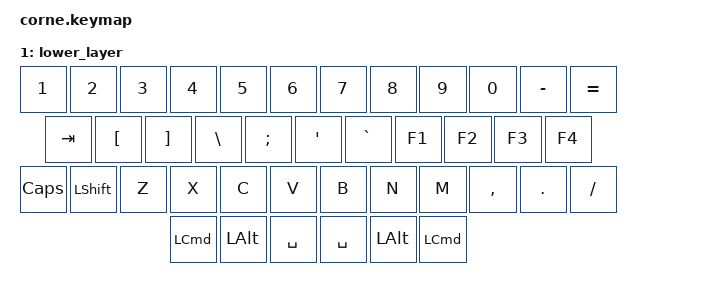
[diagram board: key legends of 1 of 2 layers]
#include <behaviors.dtsi>
#include <dt-bindings/zmk/bt.h>
#include <dt-bindings/zmk/keys.h>
#include <dt-bindings/zmk/outputs.h>

/ {
    keymap {
        compatible = "zmk,keymap";

        default_layer {
            bindings = <
&kp Q &kp W &kp E &kp R &kp T &kp Y  &kp Y &kp U &kp I &kp O &kp P &kp BACKSPACE
&kp A &kp S &kp D &kp F &kp G       &kp H &kp J &kp K &kp L &kp SEMICOLON &kp ENTER
&kp Z &kp X &kp C &kp V &kp B       &kp N &kp M &kp COMMA &kp DOT &kp SLASH &kp RIGHT_SHIFT
            &kp LEFT_COMMAND &kp LEFT_ALT &kp SPACE &kp SPACE &kp LEFT_ALT &kp LEFT_COMMAND
            >;
        };

        lower_layer {
            bindings = <
&kp N1 &kp N2 &kp N3 &kp N4 &kp N5 &kp N6  &kp N7 &kp N8 &kp N9 &kp N0 &kp MINUS &kp EQUAL
&kp TAB &kp LEFT_BRACKET &kp RIGHT_BRACKET &kp BACKSLASH &kp SEMICOLON &kp SQT  &kp GRAVE &kp F1 &kp F2 &kp F3 &kp F4
&kp CAPS &kp LEFT_SHIFT &kp Z &kp X &kp C  &kp V &kp B &kp N &kp M &kp COMMA &kp DOT &kp SLASH
            &kp LEFT_COMMAND &kp LEFT_ALT &kp SPACE &kp SPACE &kp LEFT_ALT &kp LEFT_COMMAND
            >;
        };
    };
};
